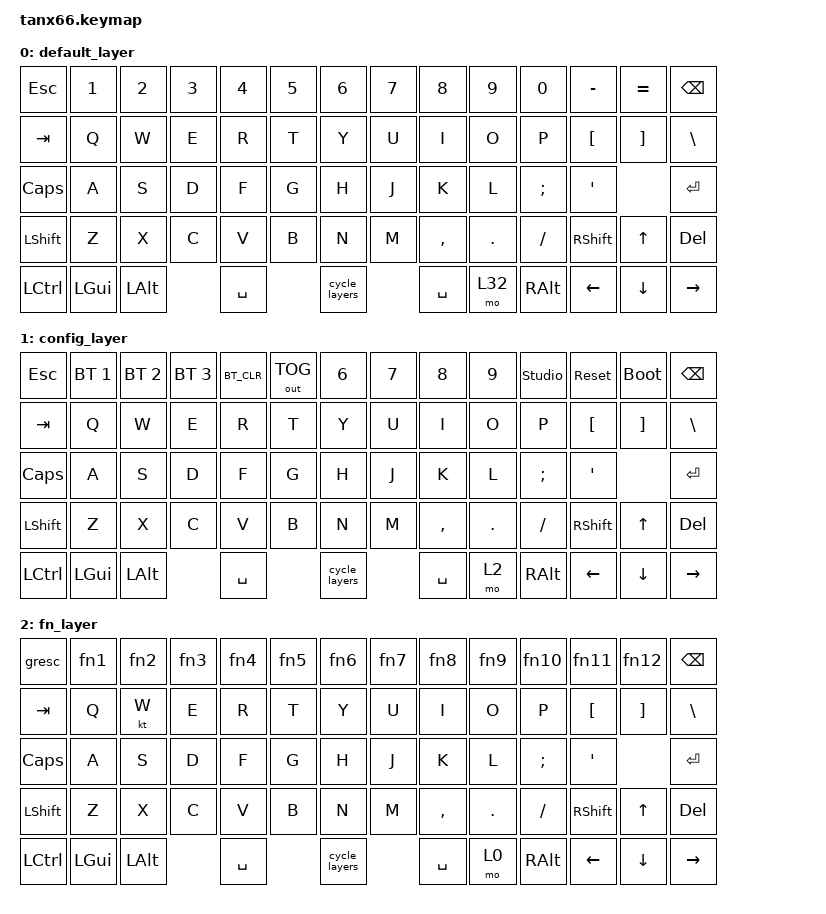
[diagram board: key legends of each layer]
/*
 * Copyright (c) 2022 The ZMK Contributors
 *
 * SPDX-License-Identifier: MIT
 */

#include <behaviors.dtsi>
#include <dt-bindings/zmk/keys.h>
#include <dt-bindings/zmk/bt.h>
#include <dt-bindings/zmk/outputs.h>


#define default_layer  0
#define config_layer   1
#define fn_layer       2

/ {
    behaviors {
        cycle_layers: behavior_macro {
            compatible = "zmk,behavior-macro";
            label = "Cycle Layers";
            #binding-cells = <0>;
            bindings = <
                &tog 0
                &tog 1
            >;
        };
    };
};


/ {
    keymap {
        compatible = "zmk,keymap";

        default_layer {
            bindings = <
                &kp ESC       &kp 1     &kp 2     &kp 3     &kp 4     &kp 5     &kp 6               &kp 7     &kp 8            &kp 9       &kp 0         &kp MINUS    &kp EQUAL     &kp BSPC
                &kp TAB       &kp Q     &kp W     &kp E     &kp R     &kp T     &kp Y               &kp U     &kp I            &kp O       &kp P         &kp LBKT     &kp RBKT      &kp BSLH
                &kp CAPS      &kp A     &kp S     &kp D     &kp F     &kp G     &kp H               &kp J     &kp K            &kp L       &kp SEMI      &kp SQT                    &kp ENTER
                &kp LSHFT     &kp Z     &kp X     &kp C     &kp V     &kp B     &kp N               &kp M     &kp COMMA        &kp DOT     &kp FSLH      &kp RSHFT    &kp UP        &kp DEL
                &kp LCTRL     &kp LGUI  &kp LALT            &kp SPACE           &cycle_layers                 &kp SPACE        &mo 32       &kp RALT      &kp LEFT     &kp DOWN      &kp RIGHT
            >;
        };

        config_layer {
            bindings = < 
                &kp ESC       &bt BT_SEL 1     &bt BT_SEL 2     &bt BT_SEL 3     BT_CLR        &out OUT_TOG     &kp 6               &kp 7     &kp 8            &kp 9       &studio_unlock         &sys_reset    &bootloader      &kp BSPC
                &kp TAB       &kp Q            &kp W            &kp E            &kp R         &kp T            &kp Y               &kp U     &kp I            &kp O       &kp P                  &kp LBKT      &kp RBKT         &kp BSLH
                &kp CAPS      &kp A            &kp S            &kp D            &kp F         &kp G            &kp H               &kp J     &kp K            &kp L       &kp SEMI               &kp SQT                        &kp ENTER
                &kp LSHFT     &kp Z            &kp X            &kp C            &kp V         &kp B            &kp N               &kp M     &kp COMMA        &kp DOT     &kp FSLH               &kp RSHFT     &kp UP           &kp DEL
                &kp LCTRL     &kp LGUI         &kp LALT                          &kp SPACE                      &cycle_layers                 &kp SPACE        &mo 2       &kp RALT               &kp LEFT      &kp DOWN         &kp RIGHT
            >;    
        };  
 
       fn_layer { 
            bindings = <
                &gresc        &kp fn1     &kp fn2     &kp fn3     &kp fn4     &kp fn5     &kp fn6            &kp fn7     &kp fn8            &kp fn9       &kp fn10       &kp fn11       &kp fn12      &kp BSPC
                &kp TAB       &kp Q       &kt W       &kp E       &kp R       &kp T       &kp Y              &kp U       &kp I              &kp O         &kp P          &kp LBKT       &kp RBKT      &kp BSLH
                &kp CAPS      &kp A       &kp S       &kp D       &kp F       &kp G       &kp H              &kp J       &kp K              &kp L         &kp SEMI       &kp SQT                      &kp ENTER
                &kp LSHFT     &kp Z       &kp X       &kp C       &kp V       &kp B       &kp N              &kp M       &kp COMMA          &kp DOT       &kp FSLH       &kp RSHFT      &kp UP        &kp DEL
                &kp LCTRL     &kp LGUI    &kp LALT                &kp SPACE               &cycle_layers                  &kp SPACE          &mo 0         &kp RALT       &kp LEFT       &kp DOWN      &kp RIGHT
            >;
        };
    };
};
